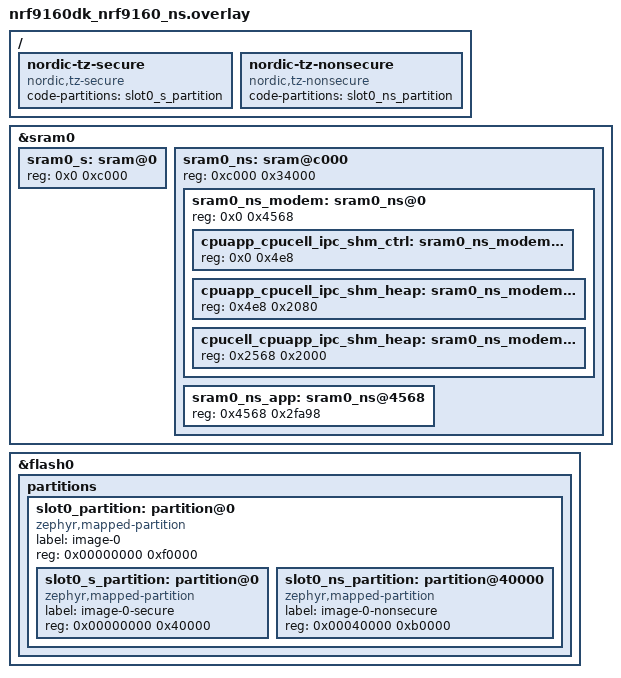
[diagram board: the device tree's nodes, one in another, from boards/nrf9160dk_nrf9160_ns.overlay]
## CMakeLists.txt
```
#
# Copyright (c) 2024 Nordic Semiconductor ASA
#
# SPDX-License-Identifier: LicenseRef-Nordic-5-Clause
#

cmake_minimum_required(VERSION 3.20.0)

find_package(Zephyr REQUIRED HINTS $ENV{ZEPHYR_BASE})
project(http_server)

target_sources(app PRIVATE src/main.c)
target_sources(app PRIVATE src/credentials_provision.c)
target_include_directories(app PRIVATE src)

if(CONFIG_NET_SOCKETS_SOCKOPT_TLS)
  message(WARNING "Credentials are exposed in non-secure memory. This should be avoided in production.")

  set(app_certs_binary_dir ${APPLICATION_BINARY_DIR}/credentials)

  # Function to process a certificate file and create a corresponding .inc file and compiler definition
  # used to assign C variables that are used in main.c.
  function(process_certificate definition_name file_name)
    set(cert_file ${APPLICATION_SOURCE_DIR}/credentials/${file_name})
    if(EXISTS ${cert_file})
      message(STATUS "${file_name} found")

      get_filename_component(file_base_name ${file_name} NAME_WE)
      set(inc_file_name ${file_base_name}.inc)

      set(inc_file_path ${app_certs_binary_dir}/${inc_file_name})
      generate_inc_file_for_target(app ${cert_file} ${inc_file_path})

      # Define a compiler macro with the path to the generated .inc file,
      # allowing it to be included in the source code.
      add_definitions(-D${definition_name}="${inc_file_path}")
    endif()
  endfunction()

  # Process each certificate file by generating a .inc file and defining a corresponding macro.
  process_certificate("HTTP_SERVER_CA_CERT" "server_certificate.pem")
  process_certificate("HTTP_SERVER_PRIVATE_KEY" "server_private_key.pem")
endif()
```

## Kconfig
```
#
# Copyright (c) 2024 Nordic Semiconductor ASA
#
# SPDX-License-Identifier: LicenseRef-Nordic-5-Clause
#

menu "HTTP server sample"

config HTTP_SERVER_SAMPLE_PEER_VERIFICATION_REQUIRE
	bool "Peer verification"
	help
	  Enable this option to make the server sample require TLS peer verification.
	  Enabling peer verification ensures that the server validates the authenticity
	  of the client during TLS/SSL handshake. This helps enhance the security of
	  communications by verifying the identity of the connecting peer.

config HTTP_SERVER_SAMPLE_PORT
	int "Server Port"
	default 443 if NET_SOCKETS_SOCKOPT_TLS
	default 80

config HTTP_SERVER_SAMPLE_CLIENTS_MAX
	int "Maximum clients"
	default 1
	help
	  This option sets the maximum number of concurrent clients.
	  Increasing this option will impact the performance of the server and increase the
	  total memory footprint as each client instance has its own thread with a dedicated stack.
	  This option sets the number of maximum concurrecnt clients per IP family, meaning that
	  if both IPv4 and IPv6 is enabled, a total of 4 clients can be connected at the same time.

config HTTP_SERVER_SAMPLE_SERVER_CERTIFICATE_SEC_TAG
	int "Server Certificate Security Tag"
	default 1
	help
	  This option sets the security tag for the credentials used in TLS.

config HTTP_SERVER_SAMPLE_STACK_SIZE
	int "Thread Stack Size"
	default 4096
	help
	  This option sets the stack size for the threads used in the sample.

config HTTP_SERVER_SAMPLE_RECEIVE_BUFFER_SIZE
	int "Receive Buffer Size"
	default 1024
	help
	  This option sets the receive buffer size for the sockets used in the sample.

module = HTTP_SERVER_SAMPLE
module-str = HTTP server sample
source "$(ZEPHYR_BASE)/subsys/logging/Kconfig.template.log_config"

# Default the TLS credentials backend by build type: NS builds use Protected
# Storage, secure-only builds fall back to the volatile backend. nRF91 keeps
# its own NRF_MODEM backend default.
choice TLS_CREDENTIALS_BACKEND
	default TLS_CREDENTIALS_BACKEND_PROTECTED_STORAGE if BUILD_WITH_TFM && !NRF_MODEM_LIB
endchoice

menu "Zephyr Kernel"
source "Kconfig.zephyr"
endmenu

endmenu
```

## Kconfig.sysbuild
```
#
# Copyright (c) 2024 Nordic Semiconductor ASA
#
# SPDX-License-Identifier: LicenseRef-Nordic-5-Clause
#

config WIFI_NRF70
	default y if BOARD_NRF7002DK_NRF5340_CPUAPP_NS || \
		BOARD_NRF54H20DK_NRF54H20_CPUAPP || \
		BOARD_NRF54LM20DK_NRF54LM20A_CPUAPP || \
		BOARD_NRF54LM20DK_NRF54LM20B_CPUAPP

config PARTITION_MANAGER
	default n

source "share/sysbuild/Kconfig"
```

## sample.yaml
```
sample:
  name: HTTP server sample
tests:
  sample.net.http_server.wifi:
    sysbuild: true
    build_only: true
    integration_platforms:
      - nrf7002dk/nrf5340/cpuapp/ns
      - nrf7120dk/nrf7120/cpuapp/ns
    platform_allow:
      - nrf7002dk/nrf5340/cpuapp/ns
      - nrf7120dk/nrf7120/cpuapp/ns
    tags:
      - ci_build
      - sysbuild
      - ci_samples_net
    extra_args:
      - http_server_EXTRA_CONF_FILE="wifi.conf"
  sample.net.http_server.wifi.tls:
    sysbuild: true
    build_only: true
    integration_platforms:
      - nrf7002dk/nrf5340/cpuapp/ns
      - nrf7120dk/nrf7120/cpuapp/ns
    platform_allow:
      - nrf7002dk/nrf5340/cpuapp/ns
      - nrf7120dk/nrf7120/cpuapp/ns
    extra_args: http_server_EXTRA_CONF_FILE="wifi.conf;wifi-tls.conf"
    tags:
      - ci_build
      - sysbuild
      - ci_samples_net
  sample.net.http_server.wifi.tls.mtls:
    sysbuild: true
    build_only: true
    integration_platforms:
      - nrf7002dk/nrf5340/cpuapp/ns
      - nrf7120dk/nrf7120/cpuapp/ns
    platform_allow:
      - nrf7002dk/nrf5340/cpuapp/ns
      - nrf7120dk/nrf7120/cpuapp/ns
    extra_args: http_server_EXTRA_CONF_FILE="wifi.conf;wifi-tls.conf"
    # Enables peer verification (mutual TLS); see the README "Security" section.
    extra_configs:
      - CONFIG_HTTP_SERVER_SAMPLE_PEER_VERIFICATION_REQUIRE=y
    tags:
      - ci_build
      - sysbuild
      - ci_samples_net
  sample.net.http_server.lte:
    sysbuild: true
    build_only: true
    integration_platforms:
      - nrf9151dk/nrf9151/ns
    platform_allow:
      - nrf9151dk/nrf9151/ns
    tags:
      - ci_build
      - sysbuild
      - ci_samples_net
  sample.net.http_server.lte.tls:
    sysbuild: true
    build_only: true
    integration_platforms:
      - nrf9151dk/nrf9151/ns
    platform_allow:
      - nrf9151dk/nrf9151/ns
    extra_args: EXTRA_CONF_FILE=overlay-tls-nrf91.conf
    tags:
      - ci_build
      - sysbuild
      - ci_samples_net
  sample.net.http_server.emulation:
    build_only: true
    integration_platforms:
      - native_sim
    platform_allow:
      - native_sim
    tags:
      - ci_build
      - ci_samples_net
  sample.net.http_server.nrf54h20.wifi:
    sysbuild: true
    build_only: true
    integration_platforms:
      - nrf54h20dk/nrf54h20/cpuapp
    platform_allow:
      - nrf54h20dk/nrf54h20/cpuapp
    tags:
      - ci_build
      - sysbuild
      - ci_samples_net
    extra_args:
      - http_server_SHIELD="nrf7002eb_interposer_p1;nrf7002eb"
      - http_server_SNIPPET="nrf70-wifi;wifi-credentials"
      - http_server_EXTRA_CONF_FILE="wifi.conf"
  sample.net.http_server.nrf54lm20_nrf7002eb2.wifi:
    sysbuild: true
    build_only: true
    integration_platforms:
      - nrf54lm20dk/nrf54lm20a/cpuapp
      - nrf54lm20dk/nrf54lm20b/cpuapp
    platform_allow:
      - nrf54lm20dk/nrf54lm20a/cpuapp
      - nrf54lm20dk/nrf54lm20b/cpuapp
    tags:
      - ci_build
      - sysbuild
      - ci_samples_net
    extra_args:
      - http_server_SHIELD="nrf7002eb2"
      - http_server_SNIPPET=wifi-credentials
      - http_server_EXTRA_CONF_FILE="wifi.conf"
```

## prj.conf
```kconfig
#
# Copyright (c) 2024 Nordic Semiconductor ASA
#
# SPDX-License-Identifier: LicenseRef-Nordic-5-Clause
#

# General
CONFIG_LOG=y
CONFIG_ASSERT=y
CONFIG_MAIN_STACK_SIZE=4096
CONFIG_TEST_RANDOM_GENERATOR=y
CONFIG_RESET_ON_FATAL_ERROR=n

# LTO
CONFIG_LTO=y
CONFIG_ISR_TABLES_LOCAL_DECLARATION=y

# LED Control
CONFIG_DK_LIBRARY=y

# Networking config
CONFIG_NETWORKING=y
CONFIG_NET_CONNECTION_MANAGER=y
CONFIG_NET_IPV4=y
CONFIG_NET_IPV6=y
CONFIG_NET_TCP=y
CONFIG_NET_UDP=y
CONFIG_NET_SOCKETS=y
CONFIG_POSIX_API=y
CONFIG_NET_MAX_CONN=10
CONFIG_NET_MAX_CONTEXTS=20

# Network buffers
CONFIG_NET_PKT_RX_COUNT=64
CONFIG_NET_PKT_TX_COUNT=48
CONFIG_NET_BUF_RX_COUNT=96
CONFIG_NET_BUF_TX_COUNT=72

# HTTP
CONFIG_HTTP_PARSER=y
CONFIG_HTTP_PARSER_URL=y
```

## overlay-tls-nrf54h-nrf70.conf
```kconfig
#
# Copyright (c) 2026 Nordic Semiconductor ASA
#
# SPDX-License-Identifier: LicenseRef-Nordic-5-Clause
#

# NET sockets
CONFIG_NET_SOCKETS_SOCKOPT_TLS=y
CONFIG_NET_SOCKETS_TLS_MAX_CONTEXTS=3

# nRF Security legacy MBed TLS
CONFIG_NORDIC_SECURITY_BACKEND=y
CONFIG_MBEDTLS_HEAP_SIZE=81920
CONFIG_HEAP_MEM_POOL_IGNORE_MIN=y
# Legacy API is required for RSA
CONFIG_MBEDTLS_LEGACY_CRYPTO_C=y
CONFIG_MBEDTLS_RSA_C=y
CONFIG_PSA_WANT_KEY_TYPE_RSA_KEY_PAIR_IMPORT=y
CONFIG_PSA_WANT_KEY_TYPE_RSA_KEY_PAIR_EXPORT=y
CONFIG_PSA_WANT_KEY_TYPE_RSA_KEY_PAIR_GENERATE=y
# Set MPI (Multiple Precision Integer) size limit to 512 bytes for handling of 4 kb certificates
# in cryptographic operations.
CONFIG_MBEDTLS_MPI_MAX_SIZE=512
# ECDH/ECDSA are needed for TLS handshake
CONFIG_PSA_WANT_ALG_ECDH=y
CONFIG_PSA_WANT_ALG_ECDSA=y

# TLS credentials
CONFIG_TLS_CREDENTIALS_BACKEND_PROTECTED_STORAGE=y
```

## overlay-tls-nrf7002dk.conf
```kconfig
#
# Copyright (c) 2024 Nordic Semiconductor ASA
#
# SPDX-License-Identifier: LicenseRef-Nordic-5-Clause
#

# NET sockets
CONFIG_NET_SOCKETS_SOCKOPT_TLS=y
CONFIG_NET_SOCKETS_TLS_MAX_CONTEXTS=3

CONFIG_PSA_CRYPTO=y
CONFIG_MBEDTLS_HEAP_SIZE=81920
CONFIG_HEAP_MEM_POOL_IGNORE_MIN=y
CONFIG_MBEDTLS_DECLARE_PRIVATE_IDENTIFIERS=y
# Pregenerated credentials in the sample are PEM-encoded.
CONFIG_MBEDTLS_PEM_PARSE_C=y
CONFIG_MBEDTLS_MD_C=y
CONFIG_MBEDTLS_HMAC_DRBG_C=y
CONFIG_MBEDTLS_SHA256_C=y
CONFIG_MBEDTLS_ECP_C=y
CONFIG_MBEDTLS_CTR_DRBG_C=y
CONFIG_MBEDTLS_AES_C=y
CONFIG_MBEDTLS_ENTROPY_C=y
CONFIG_MBEDTLS_RSA_C=y
CONFIG_PSA_WANT_KEY_TYPE_RSA_KEY_PAIR_IMPORT=y
CONFIG_PSA_WANT_KEY_TYPE_RSA_KEY_PAIR_EXPORT=y
CONFIG_PSA_WANT_KEY_TYPE_RSA_KEY_PAIR_GENERATE=y
# Set MPI (Multiple Precision Integer) size limit to 512 bytes for handling of 4 kb certificates
# in cryptographic operations.
CONFIG_MBEDTLS_MPI_MAX_SIZE=512
# ECDH/ECDSA are needed for TLS handshake
CONFIG_PSA_WANT_ALG_ECDH=y
CONFIG_PSA_WANT_ALG_ECDSA=y

# TLS credentials
CONFIG_TLS_CREDENTIALS_BACKEND_PROTECTED_STORAGE=y
```

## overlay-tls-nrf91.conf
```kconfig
#
# Copyright (c) 2024 Nordic Semiconductor ASA
#
# SPDX-License-Identifier: LicenseRef-Nordic-5-Clause
#

# NET sockets
CONFIG_NET_SOCKETS_SOCKOPT_TLS=y
CONFIG_NET_SOCKETS_TLS_MAX_CONTEXTS=2

CONFIG_PSA_CRYPTO=y
CONFIG_MBEDTLS_ENABLE_HEAP=y
CONFIG_MBEDTLS_HEAP_SIZE=51200
CONFIG_MBEDTLS_DECLARE_PRIVATE_IDENTIFIERS=y
# Pregenerated credentials in the sample are PEM-encoded.
CONFIG_MBEDTLS_PEM_PARSE_C=y
CONFIG_MBEDTLS_MD_C=y
CONFIG_MBEDTLS_HMAC_DRBG_C=y

CONFIG_PSA_WANT_ALG_RSA_PKCS1V15_CRYPT=y
CONFIG_PSA_WANT_ALG_RSA_PKCS1V15_SIGN=y
CONFIG_PSA_WANT_ALG_RSA_PSS=y
CONFIG_PSA_WANT_ALG_RSA_OAEP=y
CONFIG_PSA_WANT_RSA_KEY_SIZE_2048=y
CONFIG_PSA_WANT_KEY_TYPE_RSA_KEY_PAIR_IMPORT=y
CONFIG_PSA_WANT_KEY_TYPE_RSA_KEY_PAIR_EXPORT=y
CONFIG_PSA_WANT_KEY_TYPE_RSA_KEY_PAIR_DERIVE=y
CONFIG_PSA_WANT_KEY_TYPE_RSA_KEY_PAIR_GENERATE=y

CONFIG_MBEDTLS=y
CONFIG_MBEDTLS_SSL_SRV_C=y
CONFIG_MBEDTLS_SSL_IN_CONTENT_LEN=4096
CONFIG_MBEDTLS_SSL_OUT_CONTENT_LEN=4096

# Enable TLS protocol options
CONFIG_NET_SOCKETS_TLS_SET_MAX_FRAGMENT_LENGTH=y
CONFIG_MBEDTLS_SSL_SERVER_NAME_INDICATION=y

# Enable AES
CONFIG_PSA_WANT_KEY_TYPE_AES=y
CONFIG_PSA_WANT_ALG_CBC_PKCS7=y
CONFIG_PSA_WANT_ALG_CBC_NO_PADDING=y
CONFIG_PSA_WANT_ALG_CCM=y
CONFIG_PSA_WANT_ALG_GCM=y
CONFIG_MBEDTLS_PKCS5_C=y

# Enable ECC
CONFIG_PSA_WANT_ECC_SECP_R1_256=y
CONFIG_PSA_WANT_KEY_TYPE_ECC_KEY_PAIR_IMPORT=y
CONFIG_PSA_WANT_KEY_TYPE_ECC_KEY_PAIR_EXPORT=y
CONFIG_PSA_WANT_KEY_TYPE_ECC_KEY_PAIR_GENERATE=y
CONFIG_PSA_WANT_KEY_TYPE_ECC_KEY_PAIR_DERIVE=y

# Enable ECDSA
CONFIG_PSA_WANT_ALG_ECDSA=y
CONFIG_PSA_WANT_ALG_DETERMINISTIC_ECDSA=y
CONFIG_PSA_WANT_ALG_HMAC=y # dependency for DETERMINISTIC_ECDSA
CONFIG_PSA_WANT_KEY_TYPE_ECC_KEY_PAIR_IMPORT=y # dependency for DETERMINISTIC_ECDSA

# Enable ECDH
CONFIG_PSA_WANT_ALG_ECDH=y
CONFIG_PSA_WANT_ALG_ECDH=y

# Enable EDCHE
CONFIG_MBEDTLS_KEY_EXCHANGE_ECDHE_ECDSA_ENABLED=y
CONFIG_MBEDTLS_KEY_EXCHANGE_ECDHE_RSA_ENABLED=y

# Enable RSA
CONFIG_MBEDTLS_MPI_MAX_SIZE=512
CONFIG_PSA_WANT_KEY_TYPE_RSA_PUBLIC_KEY=y
CONFIG_PSA_WANT_RSA_KEY_SIZE_2048=y

# Enable SHA
CONFIG_PSA_WANT_ALG_SHA_256=y
CONFIG_PSA_WANT_ALG_SHA_512=y

# Disable MBEDTLS modules
CONFIG_MBEDTLS_CTR_DRBG_C=n
```

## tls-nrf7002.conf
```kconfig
#
# Copyright (c) 2024 Nordic Semiconductor ASA
#
# SPDX-License-Identifier: LicenseRef-Nordic-5-Clause
#

# NET sockets
CONFIG_NET_SOCKETS_SOCKOPT_TLS=y
CONFIG_NET_SOCKETS_TLS_MAX_CONTEXTS=3

CONFIG_MBEDTLS_HEAP_SIZE=81920
CONFIG_MBEDTLS_DECLARE_PRIVATE_IDENTIFIERS=y
# Pregenerated credentials in the sample are PEM-encoded.
CONFIG_MBEDTLS_PEM_PARSE_C=y
CONFIG_MBEDTLS_MD_C=y
CONFIG_MBEDTLS_HMAC_DRBG_C=y
CONFIG_MBEDTLS_SHA256_C=y
CONFIG_MBEDTLS_ECP_C=y
CONFIG_MBEDTLS_CTR_DRBG_C=y
CONFIG_MBEDTLS_AES_C=y
CONFIG_MBEDTLS_ENTROPY_C=y
CONFIG_MBEDTLS_RSA_C=y
CONFIG_PSA_WANT_KEY_TYPE_RSA_KEY_PAIR_IMPORT=y
CONFIG_PSA_WANT_KEY_TYPE_RSA_KEY_PAIR_EXPORT=y
CONFIG_PSA_WANT_KEY_TYPE_RSA_KEY_PAIR_GENERATE=y
# Set MPI (Multiple Precision Integer) size limit to 512 bytes for handling of 4 kb certificates
# in cryptographic operations.
CONFIG_MBEDTLS_MPI_MAX_SIZE=512
# ECDH/ECDSA are needed for TLS handshake
CONFIG_PSA_WANT_ALG_ECDH=y
CONFIG_PSA_WANT_ALG_ECDSA=y

# TLS credentials
CONFIG_TLS_CREDENTIALS_BACKEND_PROTECTED_STORAGE=y
```

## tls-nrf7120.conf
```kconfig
#
# Copyright (c) 2026 Nordic Semiconductor ASA
#
# SPDX-License-Identifier: LicenseRef-Nordic-5-Clause
#

# NET sockets
CONFIG_NET_SOCKETS_SOCKOPT_TLS=y
CONFIG_NET_SOCKETS_TLS_MAX_CONTEXTS=3

CONFIG_MBEDTLS_HEAP_SIZE=81920
CONFIG_MBEDTLS_DECLARE_PRIVATE_IDENTIFIERS=y
# Pregenerated credentials in the sample are PEM-encoded.
CONFIG_MBEDTLS_PEM_PARSE_C=y
CONFIG_MBEDTLS_MD_C=y
CONFIG_MBEDTLS_HMAC_DRBG_C=y
CONFIG_MBEDTLS_SHA256_C=y
CONFIG_MBEDTLS_ECP_C=y
CONFIG_MBEDTLS_CTR_DRBG_C=y
CONFIG_MBEDTLS_AES_C=y
CONFIG_MBEDTLS_ENTROPY_C=y
CONFIG_MBEDTLS_RSA_C=y
CONFIG_PSA_WANT_KEY_TYPE_RSA_KEY_PAIR_IMPORT=y
CONFIG_PSA_WANT_KEY_TYPE_RSA_KEY_PAIR_EXPORT=y
CONFIG_PSA_WANT_KEY_TYPE_RSA_KEY_PAIR_GENERATE=y
# Set MPI (Multiple Precision Integer) size limit to 512 bytes for handling of 4 kb certificates
# in cryptographic operations.
CONFIG_MBEDTLS_MPI_MAX_SIZE=512
# ECDH/ECDSA are needed for TLS handshake
CONFIG_PSA_WANT_ALG_ECDH=y
CONFIG_PSA_WANT_ALG_ECDSA=y

# CRACEN auto-enables CHACHA20_POLY1305 and certain ECC algorithms. Clients
# pick these ciphers; psa_import_key then fails unless the matching key types
# and curves are explicitly declared here.
CONFIG_PSA_WANT_ECC_SECP_R1_256=y
CONFIG_PSA_WANT_ECC_SECP_R1_384=y
CONFIG_PSA_WANT_ALG_ECDSA_ANY=y
CONFIG_PSA_WANT_KEY_TYPE_CHACHA20=y

# Necessary for TLS on TF-M builds
CONFIG_TFM_CRYPTO_IOVEC_BUFFER_SIZE=36864

# TLS credentials: protected storage not supported yet
CONFIG_TLS_CREDENTIALS_BACKEND_VOLATILE=y
```

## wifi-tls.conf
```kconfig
#
# Copyright (c) 2024 Nordic Semiconductor ASA
#
# SPDX-License-Identifier: LicenseRef-Nordic-5-Clause
#

# NET sockets
CONFIG_NET_SOCKETS_SOCKOPT_TLS=y
CONFIG_NET_SOCKETS_TLS_MAX_CONTEXTS=3

CONFIG_MBEDTLS_HEAP_SIZE=81920
# Pregenerated credentials in the sample are PEM-encoded.
CONFIG_MBEDTLS_PEM_PARSE_C=y
# Set MPI (Multiple Precision Integer) size limit to 512 bytes for handling of 4 kb certificates
# in cryptographic operations.
CONFIG_MBEDTLS_MPI_MAX_SIZE=512
# TLS ciphersuites: the server presents an RSA-2048 certificate, so use ECDHE_RSA
# suites. Enable several so common clients (browsers/curl) can negotiate.
CONFIG_MBEDTLS_CIPHERSUITE_TLS_ECDHE_RSA_WITH_AES_128_GCM_SHA256=y
CONFIG_MBEDTLS_CIPHERSUITE_TLS_ECDHE_RSA_WITH_AES_256_GCM_SHA384=y
CONFIG_MBEDTLS_CIPHERSUITE_TLS_ECDHE_RSA_WITH_AES_128_CBC_SHA256=y
# EC curve required for the ECDHE key exchange. P-256 is already implied by the
# ciphersuites above; P-384 is added explicitly.
CONFIG_PSA_WANT_ECC_SECP_R1_384=y
CONFIG_PSA_WANT_ALG_ECDSA_ANY=y
CONFIG_PSA_WANT_KEY_TYPE_CHACHA20=y

# Increase to accommodate mbedTLS RSA operations.
CONFIG_HTTP_SERVER_SAMPLE_STACK_SIZE=8192
```

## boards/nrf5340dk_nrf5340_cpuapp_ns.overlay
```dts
/*
 * Copyright (c) 2026 Nordic Semiconductor ASA
 *
 * SPDX-License-Identifier: LicenseRef-Nordic-5-Clause
 */

/delete-node/ &boot_partition;
/delete-node/ &slot0_partition;
/delete-node/ &slot1_partition;
/delete-node/ &tfm_its_partition;
/delete-node/ &tfm_otp_partition;
/delete-node/ &tfm_ps_partition;
/delete-node/ &storage_partition;

&flash0 {
	partitions {
		slot0_s_partition: partition@0 {
			compatible = "zephyr,mapped-partition";
			label = "image-0-secure";
			reg = <0x0 0x20000>;
		};

		slot0_ns_partition: partition@20000 {
			compatible = "zephyr,mapped-partition";
			label = "image-0-nonsecure";
			reg = <0x20000 0xd4000>;
		};

		tfm_storage_partition: partition@f4000 {
			compatible = "zephyr,mapped-partition";
			label = "tfm-storage";
			reg = <0xf4000 DT_SIZE_K(48)>;
			ranges = <0x0 0xf4000 DT_SIZE_K(48)>;
			#address-cells = <1>;
			#size-cells = <1>;

			tfm_its_partition: partition@0 {
				compatible = "zephyr,mapped-partition";
				label = "tfm-its";
				reg = <0x0 DT_SIZE_K(8)>;
			};

			tfm_otp_partition: partition@4000 {
				compatible = "zephyr,mapped-partition";
				label = "tfm-otp";
				reg = <0x4000 DT_SIZE_K(8)>;
			};

			tfm_ps_partition: partition@8000 {
				compatible = "zephyr,mapped-partition";
				label = "tfm-ps";
				reg = <0x8000 DT_SIZE_K(16)>;
			};
		};
	};
};

/*
 * TrustZone SRAM split from devicetree (region_defs.h for TF-M). The secure image uses
 * 48 KiB (0xc000) at the base of cpuapp SRAM (&sram0_s); NS RAM begins at 0x20000000 + 0xc000.
 * &sram0_ns spans 0x74000 bytes; &sram0_ns_app is 0x64000 because the top 0x10000 (64 KiB)
 * within that NS window is sram0_shared for application/network-core IPC
 * (nrf5340_shared_sram_partition.dtsi), i.e. 0x64000 + 0x10000 == 0x74000.
 */
&sram0_s {
	reg = <0x0 0xc000>;
};

&sram0_ns {
	reg = <0xc000 0x74000>;
	ranges = <0x0 0xc000 0x74000>;
};

&sram0_ns_app {
	reg = <0x0 0x64000>;
};
```

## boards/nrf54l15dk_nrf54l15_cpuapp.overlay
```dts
/*
 * Copyright (c) 2025 Nordic Semiconductor ASA
 *
 * SPDX-License-Identifier: LicenseRef-Nordic-5-Clause
 */

/delete-node/ &boot_partition;
/delete-node/ &slot0_partition;
/delete-node/ &slot1_partition;
/delete-node/ &storage_partition;

&cpuapp_rram {
	partitions {
		slot0_partition: partition@0 {
			compatible = "zephyr,mapped-partition";
			label = "image-0";
			reg = <0x0 0x17b000>;
		};

		storage_partition: partition@17b000 {
			compatible = "zephyr,mapped-partition";
			label = "storage";
			reg = <0x17b000 0x2000>;
		};
	};
};
```

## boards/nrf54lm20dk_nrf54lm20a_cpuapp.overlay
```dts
/*
 * Copyright (c) 2026 Nordic Semiconductor ASA
 *
 * SPDX-License-Identifier: LicenseRef-Nordic-5-Clause
 */

/delete-node/ &boot_partition;
/delete-node/ &slot0_partition;
/delete-node/ &slot1_partition;
/delete-node/ &storage_partition;

&cpuapp_rram {
	partitions {
		slot0_partition: partition@0 {
			compatible = "zephyr,mapped-partition";
			label = "image-0";
			reg = <0x0 0x1fb000>;
		};

		storage_partition: partition@1fb000 {
			compatible = "zephyr,mapped-partition";
			label = "storage";
			reg = <0x1fb000 0x2000>;
		};
	};
};
```

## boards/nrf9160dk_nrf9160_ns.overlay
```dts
/*
 * Copyright (c) 2026 Nordic Semiconductor ASA
 *
 * SPDX-License-Identifier: LicenseRef-Nordic-5-Clause
 */

/* Customise both TFM and APP partitions so both will fit. */
/delete-node/ &sram0_s;
/delete-node/ &sram0_ns;

&sram0 {
	/*
	 * 0x2000_0000  Secure RAM                      (   48 kB)
	 * 0x2000_c000  Non-secure RAM area             (  208 kB)
	 *   0x2000_c000  Modem shared area             ( 17768 B)
	 *     0x2000_c000  control                     (  1256 B)
	 *     0x2000_c4e8  app -> cell                 (  8320 B)
	 *     0x2000_e568  cell -> app                 (    8 kB)
	 *   0x2001_0568  Application RAM               (195224 B)
	 */
	sram0_s: sram@0 {
		reg = <0x0 0xc000>;
	};

	sram0_ns: sram@c000 {
		reg = <0xc000 0x34000>;
		#address-cells = <1>;
		#size-cells = <1>;
		ranges = <0x0 0xc000 0x34000>;

		/* Must be in first 128 kB of RAM. */
		sram0_ns_modem: sram0_ns@0 {
			/* Modem (shared) memory */
			reg = <0x0 0x4568>;
			#address-cells = <1>;
			#size-cells = <1>;
			ranges = <0x0 0x0 0x4568>;

			cpuapp_cpucell_ipc_shm_ctrl: sram0_ns_modem@0 {
				/* Modem IPC control */
				reg = <0x0 0x4e8>;
			};

			cpuapp_cpucell_ipc_shm_heap: sram0_ns_modem@4e8 {
				/* Modem IPC transmit */
				reg = <0x4e8 0x2080>;
			};

			cpucell_cpuapp_ipc_shm_heap: sram0_ns_modem@2568 {
				/* Modem IPC receive */
				reg = <0x2568 0x2000>;
			};
		};

		sram0_ns_app: sram0_ns@4568 {
			/* Non-Secure application memory */
			reg = <0x4568 0x2fa98>;
		};
	};
};

/delete-node/ &boot_partition;
/delete-node/ &slot0_partition;
/delete-node/ &slot1_partition;

&flash0 {
	/*
	 * 0x0000_0000  Primary area			(960 kB)
	 *   0x0000_0000  Primary secure image		(256 kB)
	 *   0x0004_0000  Primary non-secure image	(704 kB)
	 *
	 * Unchanged:
	 * 0x000f_0000 Protected Storage Area           ( 16 KB)
	 * 0x000f_4000 Internal Trusted Storage Area    (  8 KB)
	 * 0x000f_6000 OTP / NV counters area           (  8 KB)
	 * 0x000f_8000  Settings storage		( 32 kB)
	 */
	partitions {
		ranges;
		#address-cells = <1>;
		#size-cells = <1>;

		slot0_partition: partition@0 {
			compatible = "zephyr,mapped-partition";
			label = "image-0";
			reg = <0x00000000 0xf0000>;
			ranges = <0x0 0x00000000 0xf0000>;
			#address-cells = <1>;
			#size-cells = <1>;

			slot0_s_partition: partition@0 {
				compatible = "zephyr,mapped-partition";
				label = "image-0-secure";
				reg = <0x00000000 0x40000>;
			};

			slot0_ns_partition: partition@40000 {
				compatible = "zephyr,mapped-partition";
				label = "image-0-nonsecure";
				reg = <0x00040000 0xb0000>;
			};
		};
	};
};

/ {
	/delete-node/ nordic-tz-secure;
	/delete-node/ nordic-tz-nonsecure;

	nordic-tz-secure {
		compatible = "nordic,tz-secure";
		code-partitions = <&slot0_s_partition>;
	};

	nordic-tz-nonsecure {
		compatible = "nordic,tz-nonsecure";
		code-partitions = <&slot0_ns_partition>;
	};
};
```

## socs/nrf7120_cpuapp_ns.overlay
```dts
/*
 * Copyright (c) 2026 Nordic Semiconductor ASA
 *
 * SPDX-License-Identifier: LicenseRef-Nordic-5-Clause
 */

#include <wifi/nrf7120_wifi_patch_0_1_0.dtsi>
```

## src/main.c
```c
/*
 * Copyright (c) 2019 Intel Corporation
 * Copyright (c) 2024 Nordic Semiconductor ASA
 *
 * SPDX-License-Identifier: Apache-2.0
 */

#include <stdio.h>
#include <errno.h>

#include <zephyr/kernel.h>
#include <zephyr/logging/log.h>
#include <zephyr/logging/log_ctrl.h>
#include <zephyr/net/net_ip.h>
#include <zephyr/net/dns_sd.h>
#include <zephyr/net/socket.h>
#include <zephyr/sys/reboot.h>

#include <zephyr/net/net_config.h>
#include <zephyr/net/net_mgmt.h>
#include <zephyr/net/net_event.h>
#include <zephyr/net/conn_mgr_connectivity.h>

#include <zephyr/net/http/client.h>
#include <zephyr/net/http/parser.h>

#include <dk_buttons_and_leds.h>

#if defined(CONFIG_POSIX_API)
#include <zephyr/posix/arpa/inet.h>
#include <zephyr/posix/netdb.h>
#include <zephyr/posix/unistd.h>
#include <zephyr/posix/sys/socket.h>
#endif

#include "credentials_provision.h"

LOG_MODULE_REGISTER(http_server, CONFIG_HTTP_SERVER_SAMPLE_LOG_LEVEL);

#define SERVER_PORT			CONFIG_HTTP_SERVER_SAMPLE_PORT
#define MAX_CLIENT_QUEUE		CONFIG_HTTP_SERVER_SAMPLE_CLIENTS_MAX
#define STACK_SIZE			CONFIG_HTTP_SERVER_SAMPLE_STACK_SIZE
#define THREAD_PRIORITY			K_PRIO_COOP(CONFIG_NUM_COOP_PRIORITIES - 1)

/* Macro used to subscribe to specific Zephyr NET management events. */
#define L4_EVENT_MASK (NET_EVENT_L4_CONNECTED | NET_EVENT_L4_DISCONNECTED)
#define CONN_LAYER_EVENT_MASK (NET_EVENT_CONN_IF_FATAL_ERROR)

/* Macro called upon a fatal error, reboots the device. */
#define FATAL_ERROR()								\
	LOG_ERR("Fatal error!%s", IS_ENABLED(CONFIG_RESET_ON_FATAL_ERROR) ?	\
				  " Rebooting the device" : "");		\
	LOG_PANIC();								\
	IF_ENABLED(CONFIG_REBOOT, (sys_reboot(0)))

#if defined(CONFIG_NET_HOSTNAME)
/* Register service */
DNS_SD_REGISTER_TCP_SERVICE(http_server_sd, CONFIG_NET_HOSTNAME, "_http", "local",
			    DNS_SD_EMPTY_TXT, SERVER_PORT);
#endif /* CONFIG_NET_HOSTNAME */

struct http_req {
	struct http_parser parser;
	int socket;
	bool received_all;
	enum http_method method;
	const char *url;
	size_t url_len;
	const char *body;
	size_t body_len;
};

/* Forward declarations */
static void process_tcp4(void);
static void process_tcp6(void);

/* Keep track of the current LED states. 0 = LED OFF, 1 = LED ON.
 * Index 0 corresponds to LED1, index 1 to LED2.
 */
static uint8_t led_states[2];

/* HTTP responses for demonstration */
#define RESPONSE_200 "HTTP/1.1 200 OK\r\n"
#define RESPONSE_400 "HTTP/1.1 400 Bad Request\r\n\r\n"
#define RESPONSE_403 "HTTP/1.1 403 Forbidden\r\n\r\n"
#define RESPONSE_404 "HTTP/1.1 404 Not Found\r\n\r\n"
#define RESPONSE_405 "HTTP/1.1 405 Method Not Allowed\r\n\r\n"
#define RESPONSE_500 "HTTP/1.1 500 Internal Server Error\r\n\r\n"

/* Processing threads for incoming connections */
K_THREAD_STACK_ARRAY_DEFINE(tcp4_handler_stack, MAX_CLIENT_QUEUE, STACK_SIZE);
static struct k_thread tcp4_handler_thread[MAX_CLIENT_QUEUE];
static k_tid_t tcp4_handler_tid[MAX_CLIENT_QUEUE];
K_THREAD_DEFINE(tcp4_thread_id, STACK_SIZE,
		process_tcp4, NULL, NULL, NULL,
		THREAD_PRIORITY, 0, -1);

K_THREAD_STACK_ARRAY_DEFINE(tcp6_handler_stack, MAX_CLIENT_QUEUE, STACK_SIZE);
static struct k_thread tcp6_handler_thread[MAX_CLIENT_QUEUE];
static k_tid_t tcp6_handler_tid[MAX_CLIENT_QUEUE];
K_THREAD_DEFINE(tcp6_thread_id, STACK_SIZE,
		process_tcp6, NULL, NULL, NULL,
		THREAD_PRIORITY, 0, -1);

static K_SEM_DEFINE(network_connected_sem, 0, 1);
static K_SEM_DEFINE(ipv6_setup_sem, 0, 1);

static int tcp4_sock;
static int tcp4_accepted[MAX_CLIENT_QUEUE];
static int tcp6_sock;
static int tcp6_accepted[MAX_CLIENT_QUEUE];

static struct http_parser_settings parser_settings;

static void l4_event_handler(uint64_t event, struct net_if *iface, void *info,
			     size_t info_length, void *user_data)
{
	switch (event) {
	case NET_EVENT_L4_CONNECTED:
		LOG_INF("Network connected");

		k_sem_give(&network_connected_sem);
		break;
	case NET_EVENT_L4_DISCONNECTED:
		LOG_INF("Network disconnected");
		break;
	default:
		/* Don't care */
		return;
	}
}

static void connectivity_event_handler(uint64_t event, struct net_if *iface, void *info,
				       size_t info_length, void *user_data)
{
	if (event == NET_EVENT_CONN_IF_FATAL_ERROR) {
		LOG_ERR("NET_EVENT_CONN_IF_FATAL_ERROR");
		FATAL_ERROR();
		return;
	}
}

/* Registered statically to not miss events raised before main() */
NET_MGMT_REGISTER_EVENT_HANDLER(l4_events, L4_EVENT_MASK, l4_event_handler, NULL);
NET_MGMT_REGISTER_EVENT_HANDLER(conn_events, CONN_LAYER_EVENT_MASK, connectivity_event_handler,
				NULL);

/* Update the LED states. Returns 0 if it was updated, otherwise -1. */
static int led_update(uint8_t index, uint8_t state)
{
	if (state <= 1) {
		led_states[index] = state;
	} else {
		LOG_WRN("Illegal value %d written to LED %d", state, index);
		return -EBADMSG;
	}

	if (IS_ENABLED(CONFIG_DK_LIBRARY)) {
		int ret;

		ret = dk_set_led(index, led_states[index]);
		if (ret) {
			LOG_ERR("Failed to update LED %d state to %d", index, led_states[index]);
			FATAL_ERROR();
			return -EIO;
		}
	}

	LOG_INF("LED %d state updated to %d", index, led_states[index]);

	return 0;
}

static int handle_put(struct http_req *request, char *response, size_t response_size)
{
	int ret;
	uint8_t led_id, led_index;

	if (request->body_len < 1) {
		LOG_ERR("No request body");
		return -EBADMSG;
	}

	/* Get LED ID */
	ret = sscanf(request->url, "/led/%hhu", &led_id);
	if (ret != 1) {
		LOG_WRN("Invalid URL: %s", request->url);
		return -EINVAL;
	}

	/* Get LED Index */
	if (led_id < 1 || led_id > 2) {
		LOG_ERR("Invalid LED ID: %d, valid values are 1 and 2", led_id);
		return -EINVAL;
	}

	led_index = led_id - 1;

	ret = led_update(led_index, (uint8_t)atoi(request->body));
	if (ret) {
		LOG_WRN("Update failed for LED %d", led_index);
		return ret;
	}

	ret = snprintk(response, response_size, "%sContent-Length: %d\r\n\r\n",
		       RESPONSE_200, 0);
	if ((ret < 0) || (ret >= response_size)) {
		return -ENOBUFS;
	}

	return 0;
}

static int handle_get(struct http_req *request, char *response, size_t response_size)
{
	int ret;
	char body[2];
	uint8_t led_id, led_index;

	/* Get LED ID */
	ret = sscanf(request->url, "/led/%hhu", &led_id);
	if (ret != 1) {
		LOG_WRN("Invalid URL: %s", request->url);
		return -EINVAL;
	}

	/* Get LED Index */
	if (led_id < 1 || led_id > 2) {
		LOG_ERR("Invalid LED ID: %d, valid values are 1 and 2", led_id);
		return -EINVAL;
	}

	led_index = led_id - 1;

	ret = snprintk(body, sizeof(body), "%d", led_states[led_index]);
	if ((ret < 0) || (ret >= sizeof(body))) {
		return -ENOBUFS;
	}

	ret = snprintk(response, response_size,
		       "%sContent-Type: text/plain\r\nContent-Length: %d\r\n\r\n%s",
		       RESPONSE_200, strlen(body), body);
	if ((ret < 0) || (ret >= response_size)) {
		return -ENOBUFS;
	}

	return 0;
}

static int send_response(struct http_req *request, char *response)
{
	ssize_t out_len;
	size_t len = strlen(response);

	while (len) {
		out_len = send(request->socket, response, len, 0);
		if (out_len < 0) {
			LOG_ERR("send, error: %d", -errno);
			return -errno;
		}

		len -= out_len;
	}

	return 0;
}

/* Handle HTTP request */
static void handle_http_request(struct http_req *request)
{
	int ret;
	char *resp_ptr = RESPONSE_200;
	char get_response_buffer[100] = { 0 };

	/* Handle the request method */
	switch (request->method) {
	case HTTP_PUT:
		ret = handle_put(request, get_response_buffer, sizeof(get_response_buffer));
		if (ret) {
			LOG_WRN("Incoming HTTP GET request, error: %d", ret);
			resp_ptr = (ret == -EINVAL) ? RESPONSE_404 :
				   (ret == -EBADMSG) ? RESPONSE_400 : RESPONSE_500;
			break;
		}

		resp_ptr = get_response_buffer;
		break;
	case HTTP_GET:
		ret = handle_get(request, get_response_buffer, sizeof(get_response_buffer));
		if (ret) {
			LOG_WRN("Incoming HTTP GET request, error: %d", ret);
			resp_ptr = (ret == -EINVAL) ? RESPONSE_404 : RESPONSE_500;
			break;
		}

		resp_ptr = get_response_buffer;
		break;
	default:
		LOG_WRN("Unsupported request method");
		resp_ptr = RESPONSE_405;
		break;
	}

	/* Send response */
	ret = send_response(request, resp_ptr);
	if (ret) {
		LOG_ERR("send_response, error: %d", ret);
		FATAL_ERROR();
		return;
	}
}

/* HTTP parser callbacks */
static int on_body(struct http_parser *parser, const char *at, size_t length)
{
	struct http_req *req = CONTAINER_OF(parser, struct http_req, parser);

	req->body = at;
	req->body_len = length;

	LOG_DBG("on_body: %d", parser->method);
	LOG_DBG("> %.*s", length, at);

	return 0;
}

static int on_headers_complete(struct http_parser *parser)
{
	struct http_req *req = CONTAINER_OF(parser, struct http_req, parser);

	req->method = parser->method;

	LOG_DBG("on_headers_complete, method: %s", http_method_str(parser->method));

	return 0;
}

static int on_message_begin(struct http_parser *parser)
{
	struct http_req *req = CONTAINER_OF(parser, struct http_req, parser);

	req->received_all = false;

	LOG_DBG("on_message_begin, method: %d", parser->method);

	return 0;
}

static int on_message_complete(struct http_parser *parser)
{
	struct http_req *req = CONTAINER_OF(parser, struct http_req, parser);

	req->received_all = true;

	LOG_DBG("on_message_complete, method: %d", parser->method);

	return 0;
}

static int on_url(struct http_parser *parser, const char *at, size_t length)
{
	struct http_req *req = CONTAINER_OF(parser, struct http_req, parser);

	req->url = at;
	req->url_len = length;

	LOG_DBG("on_url, method: %d", parser->method);
	LOG_DBG("> %.*s", length, at);

	return 0;
}

/* Initialize HTTP parser. */
static void parser_init(void)
{
	http_parser_settings_init(&parser_settings);

	parser_settings.on_body = on_body;
	parser_settings.on_headers_complete = on_headers_complete;
	parser_settings.on_message_begin = on_message_begin;
	parser_settings.on_message_complete = on_message_complete;
	parser_settings.on_url = on_url;
}

static int setup_server(int *sock, struct sockaddr *bind_addr, socklen_t bind_addrlen)
{
	int ret;
	int enable = 1;

	if (IS_ENABLED(CONFIG_NET_SOCKETS_SOCKOPT_TLS)) {
		/* Run the Zephyr Native TLS stack (MBed TLS) in the application core instead of
		 * using the TLS stack on the modem.
		 * This is needed because the modem does not support TLS in server mode.
		 *
		 * This is done by using (SOCK_STREAM | SOCK_NATIVE_TLS) as socket type when
		 * building for a nRF91 Series board.
		 */
		int type = IS_ENABLED(CONFIG_NRF_MODEM_LIB) ? SOCK_STREAM | SOCK_NATIVE_TLS :
							      SOCK_STREAM;

		*sock = socket(bind_addr->sa_family, type, IPPROTO_TLS_1_2);
	} else {
		*sock = socket(bind_addr->sa_family, SOCK_STREAM, IPPROTO_TCP);
	}

	if (*sock < 0) {
		LOG_ERR("Failed to create socket: %d", -errno);
		return -errno;
	}

	if (IS_ENABLED(CONFIG_NET_SOCKETS_SOCKOPT_TLS)) {
		sec_tag_t sec_tag_list[] = {
			CONFIG_HTTP_SERVER_SAMPLE_SERVER_CERTIFICATE_SEC_TAG,
		};

		ret = setsockopt(*sock, SOL_TLS, TLS_SEC_TAG_LIST,
				 sec_tag_list, sizeof(sec_tag_list));
		if (ret < 0) {
			LOG_ERR("Failed to set security tag list %d", -errno);
			return -errno;
		}

		if (IS_ENABLED(CONFIG_HTTP_SERVER_SAMPLE_PEER_VERIFICATION_REQUIRE)) {
			int require = 2;

			ret = zsock_setsockopt(*sock, SOL_TLS, TLS_PEER_VERIFY,
					       &require,
					       sizeof(require));
			if (ret < 0) {
				LOG_ERR("Failed to set peer verification option %d", -errno);
				return -errno;
			}
		}
	}

	ret = setsockopt(*sock, SOL_SOCKET, SO_REUSEADDR, &enable, sizeof(enable));
	if (ret) {
		LOG_ERR("Failed to set SO_REUSEADDR %d", -errno);
		return -errno;
	}

	ret = bind(*sock, bind_addr, bind_addrlen);
	if (ret < 0) {
		LOG_ERR("Failed to bind socket %d", -errno);
		return -errno;
	}

	ret = listen(*sock, MAX_CLIENT_QUEUE);
	if (ret < 0) {
		LOG_ERR("Failed to listen on socket %d", -errno);
		return -errno;
	}

	return ret;
}

static void client_conn_handler(void *ptr1, void *ptr2, void *ptr3)
{
	ARG_UNUSED(ptr1);
	int *sock = ptr2;
	k_tid_t *in_use = ptr3;
	int received;
	int ret;
	char buf[CONFIG_HTTP_SERVER_SAMPLE_RECEIVE_BUFFER_SIZE];
	size_t offset = 0;
	size_t total_received = 0;
	struct http_req request = {
		.socket = *sock,
	};

	http_parser_init(&request.parser, HTTP_REQUEST);

	while (true) {
		received = recv(request.socket, buf + offset, sizeof(buf) - offset, 0);
		if (received == 0) {
			/* Connection closed */
			LOG_DBG("[%d] Connection closed by peer", request.socket);
			break;
		} else if (received < 0) {
			/* Socket error */
			ret = -errno;
			LOG_ERR("[%d] Connection error %d", request.socket, ret);
			break;
		}

		/* Parse the received data as HTTP request */
		(void)http_parser_execute(&request.parser,
					  &parser_settings, buf + offset, received);

		total_received += received;
		offset += received;

		if (offset >= sizeof(buf)) {
			offset = 0;
		}

		/* If the HTTP request has been completely received, stop receiving data and
		 * proceed to process the request.
		 */
		if (request.received_all) {
			handle_http_request(&request);
			break;
		}
	};

	(void)close(request.socket);

	*sock = -1;
	*in_use = NULL;
}

static int get_free_slot(int *accepted)
{
	for (int i = 0; i < MAX_CLIENT_QUEUE; i++) {
		if (accepted[i] < 0) {
			return i;
		}
	}

	return -1;
}

static void process_tcp(sa_family_t family, int *sock, int *accepted)
{
	int client;
	int slot;
	struct sockaddr_in6 client_addr;
	socklen_t client_addr_len = sizeof(client_addr);
	char addr_str[INET6_ADDRSTRLEN];

	client = accept(*sock, (struct sockaddr *)&client_addr,
			&client_addr_len);
	if (client < 0) {
		LOG_ERR("Error in accept %d, try again", -errno);
		return;
	}

	slot = get_free_slot(accepted);
	if (slot < 0 || slot >= MAX_CLIENT_QUEUE) {
		LOG_ERR("Cannot accept more connections");
		close(client);
		return;
	}

	accepted[slot] = client;

	if (family == AF_INET6) {
		tcp6_handler_tid[slot] = k_thread_create(
			&tcp6_handler_thread[slot],
			tcp6_handler_stack[slot],
			K_THREAD_STACK_SIZEOF(tcp6_handler_stack[slot]),
			(k_thread_entry_t)client_conn_handler,
			INT_TO_POINTER(slot),
			&accepted[slot],
			&tcp6_handler_tid[slot],
			THREAD_PRIORITY,
			0, K_NO_WAIT);
		k_thread_name_set(tcp6_handler_tid[slot], "tcp6_handler");
	} else if (family == AF_INET) {
		tcp4_handler_tid[slot] = k_thread_create(
			&tcp4_handler_thread[slot],
			tcp4_handler_stack[slot],
			K_THREAD_STACK_SIZEOF(tcp4_handler_stack[slot]),
			(k_thread_entry_t)client_conn_handler,
			INT_TO_POINTER(slot),
			&accepted[slot],
			&tcp4_handler_tid[slot],
			THREAD_PRIORITY,
			0, K_NO_WAIT);
		k_thread_name_set(tcp4_handler_tid[slot], "tcp4_handler");
	}

	net_addr_ntop(client_addr.sin6_family, &client_addr.sin6_addr, addr_str, sizeof(addr_str));

	LOG_INF("[%d] Connection from %s accepted", client, addr_str);
}

/* Processing incoming IPv4 clients */
static void process_tcp4(void)
{
	int ret;
	struct sockaddr_in addr4 = {
		.sin_family = AF_INET,
		.sin_port = htons(SERVER_PORT),
	};

	ret = setup_server(&tcp4_sock, (struct sockaddr *)&addr4, sizeof(addr4));
	if (ret < 0) {
		LOG_ERR("Failed to create IPv4 socket %d", ret);
		return;
	}

	LOG_INF("Waiting for IPv4 HTTP connections on port %d, sock %d", SERVER_PORT, tcp4_sock);

	while (true) {
		process_tcp(AF_INET, &tcp4_sock, tcp4_accepted);
	}
}

/* Processing incoming IPv6 clients */
static void process_tcp6(void)
{
	int ret;
	struct sockaddr_in6 addr6 = {
		.sin6_family = AF_INET6,
		.sin6_port = htons(SERVER_PORT),
	};

	ret = setup_server(&tcp6_sock, (struct sockaddr *)&addr6, sizeof(addr6));

	k_sem_give(&ipv6_setup_sem);

	if (ret < 0) {
		LOG_ERR("Failed to create IPv6 socket %d", ret);
		return;
	}

	LOG_INF("Waiting for IPv6 HTTP connections on port %d, sock %d",
		SERVER_PORT, tcp6_sock);

	while (true) {
		process_tcp(AF_INET6, &tcp6_sock, tcp6_accepted);
	}
}

void start_listener(void)
{
	for (size_t i = 0; i < MAX_CLIENT_QUEUE; i++) {
		if (IS_ENABLED(CONFIG_NET_IPV4)) {
			tcp4_accepted[i] = -1;
			tcp4_sock = -1;
		}

		if (IS_ENABLED(CONFIG_NET_IPV6)) {
			tcp6_accepted[i] = -1;
			tcp6_sock = -1;
		}
	}

	if (IS_ENABLED(CONFIG_NET_IPV6)) {
		k_thread_start(tcp6_thread_id);

		/* Wait for the thread that sets up the IPv6 sockets to complete
		 * before starting the IPv4 thread.
		 * This is to avoid an error when secure sockets
		 * for both IP families are created at the same time in two different threads.
		 */
		k_sem_take(&ipv6_setup_sem, K_FOREVER);
	}

	if (IS_ENABLED(CONFIG_NET_IPV4)) {
		k_thread_start(tcp4_thread_id);
	}
}

int main(void)
{
	int ret;

	LOG_INF("HTTP Server sample started");

	if (IS_ENABLED(CONFIG_NET_SOCKETS_SOCKOPT_TLS)) {
		ret = credentials_provision();
		if (ret) {
			LOG_ERR("credentials_provision, error: %d", ret);
			FATAL_ERROR();
			return ret;
		}
	}

	parser_init();

	if (IS_ENABLED(CONFIG_DK_LIBRARY)) {
		ret = dk_leds_init();
		if (ret) {
			LOG_ERR("dk_leds_init, error: %d", ret);
			FATAL_ERROR();
			return ret;
		}
	}

	ret = conn_mgr_all_if_up(true);
	if (ret) {
		LOG_ERR("conn_mgr_all_if_up, error: %d", ret);
		FATAL_ERROR();
		return ret;
	}

	LOG_INF("Network interface brought up");

	ret = conn_mgr_all_if_connect(true);
	if (ret) {
		LOG_ERR("conn_mgr_all_if_connect, error: %d", ret);
		FATAL_ERROR();
		return ret;
	}

	k_sem_take(&network_connected_sem, K_FOREVER);

	start_listener();

	return 0;
}
```

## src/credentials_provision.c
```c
/*
 * Copyright (c) 2024 Nordic Semiconductor ASA
 *
 * SPDX-License-Identifier: LicenseRef-Nordic-5-Clause
 */

#include <zephyr/kernel.h>
#include <zephyr/net/tls_credentials.h>
#include <zephyr/logging/log.h>
#include <zephyr/logging/log_ctrl.h>

static const unsigned char server_certificate[] = {
#if defined(HTTP_SERVER_CA_CERT)
#include HTTP_SERVER_CA_CERT

/* Null terminate certificate */
(0x00)
#else
""
#endif
};

static const unsigned char server_private_key[] = {
#if defined(HTTP_SERVER_PRIVATE_KEY)
#include HTTP_SERVER_PRIVATE_KEY

/* Null terminate certificate */
(0x00)
#else
""
#endif
};

LOG_MODULE_REGISTER(http_server_credentials_provision, CONFIG_HTTP_SERVER_SAMPLE_LOG_LEVEL);

static int credential_add_or_replace(sec_tag_t tag, enum tls_credential_type type,
				      const void *cred, size_t credlen, const char *name)
{
	int ret;

	ret = tls_credential_add(tag, type, cred, credlen);
	if (ret == -EEXIST) {
		LOG_DBG("%s already exists, sec tag: %d, replacing", name, tag);

		ret = tls_credential_delete(tag, type);
		if (ret < 0) {
			LOG_ERR("Failed to delete stale %s: %d", name, ret);
			return ret;
		}

		ret = tls_credential_add(tag, type, cred, credlen);
	}

	if (ret < 0) {
		LOG_ERR("Failed to register %s: %d", name, ret);
	}

	return ret;
}

int credentials_provision(void)
{
	int ret;

	ret = credential_add_or_replace(CONFIG_HTTP_SERVER_SAMPLE_SERVER_CERTIFICATE_SEC_TAG,
					 TLS_CREDENTIAL_CA_CERTIFICATE,
					 server_certificate, sizeof(server_certificate),
					 "CA certificate");
	if (ret < 0) {
		return ret;
	}

	ret = credential_add_or_replace(CONFIG_HTTP_SERVER_SAMPLE_SERVER_CERTIFICATE_SEC_TAG,
					 TLS_CREDENTIAL_PUBLIC_CERTIFICATE,
					 server_certificate, sizeof(server_certificate),
					 "public certificate");
	if (ret < 0) {
		return ret;
	}

	ret = credential_add_or_replace(CONFIG_HTTP_SERVER_SAMPLE_SERVER_CERTIFICATE_SEC_TAG,
					 TLS_CREDENTIAL_PRIVATE_KEY,
					 server_private_key, sizeof(server_private_key),
					 "private key");
	if (ret < 0) {
		return ret;
	}

	return 0;
}
```

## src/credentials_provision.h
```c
/*
 * Copyright (c) 2024 Nordic Semiconductor ASA
 *
 * SPDX-License-Identifier: LicenseRef-Nordic-5-Clause
 */
#include <zephyr/net/tls_credentials.h>

int credentials_provision(void);
```
